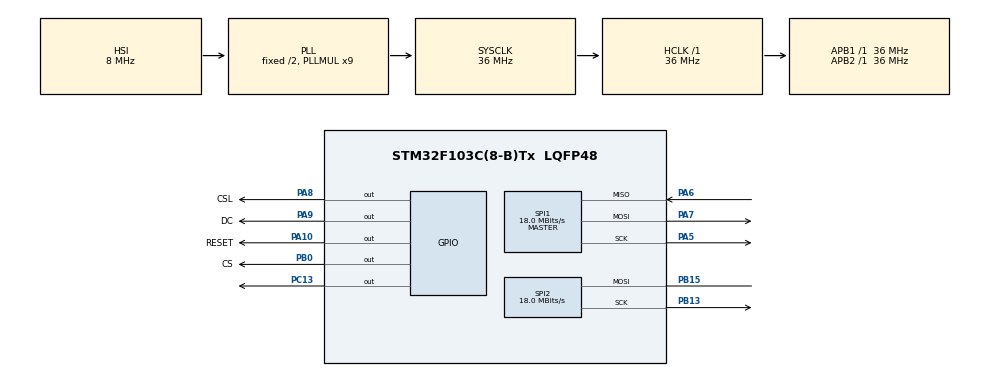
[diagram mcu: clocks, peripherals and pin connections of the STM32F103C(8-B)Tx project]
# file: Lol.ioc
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Mcu.Family=STM32F1
Mcu.Name=STM32F103C(8-B)Tx
Mcu.Package=LQFP48
NVIC.PriorityGroup=NVIC_PRIORITYGROUP_4
PA10.GPIO_Label=RESET
PA10.Signal=GPIO_Output
PA13.Mode=Serial_Wire
PA13.Signal=SYS_JTMS-SWDIO
PA14.Mode=Serial_Wire
PA14.Signal=SYS_JTCK-SWCLK
PA5.Mode=Full_Duplex_Master
PA5.Signal=SPI1_SCK
PA6.Mode=Full_Duplex_Master
PA6.Signal=SPI1_MISO
PA7.Mode=Full_Duplex_Master
PA7.Signal=SPI1_MOSI
PA8.GPIO_Label=CSL
PA8.PinState=GPIO_PIN_SET
PA8.Signal=GPIO_Output
PA9.GPIO_Label=DC
PA9.Signal=GPIO_Output
PB0.GPIO_Label=CS
PB0.Signal=GPIO_Output
PB13.Mode=Simplex_Bidirectional_Master
PB13.Signal=SPI2_SCK
PB15.Mode=Simplex_Bidirectional_Master
PB15.Signal=SPI2_MOSI
PC13-TAMPER-RTC.GPIO_PuPd=GPIO_PULLUP
PC13-TAMPER-RTC.GPIO_Speed=GPIO_SPEED_FREQ_MEDIUM
PC13-TAMPER-RTC.PinState=GPIO_PIN_SET
PC13-TAMPER-RTC.Signal=GPIO_Output
ProjectManager.HeapSize=0x200
ProjectManager.StackSize=0x400
ProjectManager.TargetToolchain=STM32CubeIDE
RCC.AHBFreq_Value=36000000
RCC.APB1Freq_Value=36000000
RCC.APB1TimFreq_Value=36000000
RCC.APB2Freq_Value=36000000
RCC.APB2TimFreq_Value=36000000
RCC.HCLKFreq_Value=36000000
RCC.PLLMUL=RCC_PLL_MUL9
RCC.SYSCLKFreq_VALUE=36000000
RCC.SYSCLKSource=RCC_SYSCLKSOURCE_PLLCLK
RCC.USBFreq_Value=36000000
SPI1.BaudRatePrescaler=SPI_BAUDRATEPRESCALER_2
SPI1.CalculateBaudRate=18.0 MBits/s
SPI1.Direction=SPI_DIRECTION_2LINES
SPI1.Mode=SPI_MODE_MASTER
SPI1.VirtualType=VM_MASTER
SPI2.BaudRatePrescaler=SPI_BAUDRATEPRESCALER_2
SPI2.CalculateBaudRate=18.0 MBits/s
SPI2.Direction=SPI_DIRECTION_1LINE
SPI2.Mode=SPI_MODE_MASTER
SPI2.VirtualType=VM_MASTER
board=custom

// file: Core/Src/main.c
/* USER CODE BEGIN Header */
/**
  ******************************************************************************
  * @file           : main.c
  * @brief          : Main program body
  ******************************************************************************
  * @attention
  *
  * Copyright (c) 2024 STMicroelectronics.
  * All rights reserved.
  *
  * This software is licensed under terms that can be found in the LICENSE file
  * in the root directory of this software component.
  * If no LICENSE file comes with this software, it is provided AS-IS.
  *
  ******************************************************************************
  */
/* USER CODE END Header */
#include "main.h"

/* USER CODE BEGIN Includes */
#include "App/app_main.h"
/* USER CODE END Includes */

SPI_HandleTypeDef hspi1;
SPI_HandleTypeDef hspi2;

void SystemClock_Config(void);
static void MX_GPIO_Init(void);
static void MX_SPI1_Init(void);
static void MX_SPI2_Init(void);

int main(void)
{

  /* MCU Configuration--------------------------------------------------------*/

  /* Reset of all peripherals, Initializes the Flash interface and the Systick. */
  HAL_Init();

  /* Configure the system clock */
  SystemClock_Config();

  /* Initialize all configured peripherals */
  MX_GPIO_Init();
  MX_SPI1_Init();
  MX_SPI2_Init();
  /* USER CODE BEGIN 2 */
  App_main();
  /* USER CODE END 2 */

  /* Infinite loop */
  while (1)
  {

  }
}

void SystemClock_Config(void)
{
  RCC_OscInitTypeDef RCC_OscInitStruct = {0};
  RCC_ClkInitTypeDef RCC_ClkInitStruct = {0};

  /** Initializes the RCC Oscillators according to the specified parameters
  * in the RCC_OscInitTypeDef structure.
  */
  RCC_OscInitStruct.OscillatorType = RCC_OSCILLATORTYPE_HSI;
  RCC_OscInitStruct.HSIState = RCC_HSI_ON;
  RCC_OscInitStruct.HSICalibrationValue = RCC_HSICALIBRATION_DEFAULT;
  RCC_OscInitStruct.PLL.PLLState = RCC_PLL_ON;
  RCC_OscInitStruct.PLL.PLLSource = RCC_PLLSOURCE_HSI_DIV2;
  RCC_OscInitStruct.PLL.PLLMUL = RCC_PLL_MUL9;
  if (HAL_RCC_OscConfig(&RCC_OscInitStruct) != HAL_OK)
  {
    Error_Handler();
  }

  /** Initializes the CPU, AHB and APB buses clocks
  */
  RCC_ClkInitStruct.ClockType = RCC_CLOCKTYPE_HCLK|RCC_CLOCKTYPE_SYSCLK
                              |RCC_CLOCKTYPE_PCLK1|RCC_CLOCKTYPE_PCLK2;
  RCC_ClkInitStruct.SYSCLKSource = RCC_SYSCLKSOURCE_PLLCLK;
  RCC_ClkInitStruct.AHBCLKDivider = RCC_SYSCLK_DIV1;
  RCC_ClkInitStruct.APB1CLKDivider = RCC_HCLK_DIV1;
  RCC_ClkInitStruct.APB2CLKDivider = RCC_HCLK_DIV1;

  if (HAL_RCC_ClockConfig(&RCC_ClkInitStruct, FLASH_LATENCY_1) != HAL_OK)
  {
    Error_Handler();
  }
}

static void MX_SPI1_Init(void)
{

  /* SPI1 parameter configuration*/
  hspi1.Instance = SPI1;
  hspi1.Init.Mode = SPI_MODE_MASTER;
  hspi1.Init.Direction = SPI_DIRECTION_2LINES;
  hspi1.Init.DataSize = SPI_DATASIZE_8BIT;
  hspi1.Init.CLKPolarity = SPI_POLARITY_LOW;
  hspi1.Init.CLKPhase = SPI_PHASE_1EDGE;
  hspi1.Init.NSS = SPI_NSS_SOFT;
  hspi1.Init.BaudRatePrescaler = SPI_BAUDRATEPRESCALER_2;
  hspi1.Init.FirstBit = SPI_FIRSTBIT_MSB;
  hspi1.Init.TIMode = SPI_TIMODE_DISABLE;
  hspi1.Init.CRCCalculation = SPI_CRCCALCULATION_DISABLE;
  hspi1.Init.CRCPolynomial = 10;
  if (HAL_SPI_Init(&hspi1) != HAL_OK)
  {
    Error_Handler();
  }

}

static void MX_SPI2_Init(void)
{

  /* SPI2 parameter configuration*/
  hspi2.Instance = SPI2;
  hspi2.Init.Mode = SPI_MODE_MASTER;
  hspi2.Init.Direction = SPI_DIRECTION_1LINE;
  hspi2.Init.DataSize = SPI_DATASIZE_8BIT;
  hspi2.Init.CLKPolarity = SPI_POLARITY_LOW;
  hspi2.Init.CLKPhase = SPI_PHASE_1EDGE;
  hspi2.Init.NSS = SPI_NSS_SOFT;
  hspi2.Init.BaudRatePrescaler = SPI_BAUDRATEPRESCALER_2;
  hspi2.Init.FirstBit = SPI_FIRSTBIT_MSB;
  hspi2.Init.TIMode = SPI_TIMODE_DISABLE;
  hspi2.Init.CRCCalculation = SPI_CRCCALCULATION_DISABLE;
  hspi2.Init.CRCPolynomial = 10;
  if (HAL_SPI_Init(&hspi2) != HAL_OK)
  {
    Error_Handler();
  }

}

static void MX_GPIO_Init(void)
{
  GPIO_InitTypeDef GPIO_InitStruct = {0};

  /* GPIO Ports Clock Enable */
  __HAL_RCC_GPIOC_CLK_ENABLE();
  __HAL_RCC_GPIOA_CLK_ENABLE();
  __HAL_RCC_GPIOB_CLK_ENABLE();

  /*Configure GPIO pin Output Level */
  HAL_GPIO_WritePin(GPIOC, GPIO_PIN_13, GPIO_PIN_SET);

  /*Configure GPIO pin Output Level */
  HAL_GPIO_WritePin(CS_GPIO_Port, CS_Pin, GPIO_PIN_RESET);

  /*Configure GPIO pin Output Level */
  HAL_GPIO_WritePin(CSL_GPIO_Port, CSL_Pin, GPIO_PIN_SET);

  /*Configure GPIO pin Output Level */
  HAL_GPIO_WritePin(GPIOA, DC_Pin|RESET_Pin, GPIO_PIN_RESET);

  /*Configure GPIO pin : PC13 */
  GPIO_InitStruct.Pin = GPIO_PIN_13;
  GPIO_InitStruct.Mode = GPIO_MODE_OUTPUT_PP;
  GPIO_InitStruct.Pull = GPIO_PULLUP;
  GPIO_InitStruct.Speed = GPIO_SPEED_FREQ_MEDIUM;
  HAL_GPIO_Init(GPIOC, &GPIO_InitStruct);

  /*Configure GPIO pin : CS_Pin */
  GPIO_InitStruct.Pin = CS_Pin;
  GPIO_InitStruct.Mode = GPIO_MODE_OUTPUT_PP;
  GPIO_InitStruct.Pull = GPIO_NOPULL;
  GPIO_InitStruct.Speed = GPIO_SPEED_FREQ_LOW;
  HAL_GPIO_Init(CS_GPIO_Port, &GPIO_InitStruct);

  /*Configure GPIO pins : CSL_Pin DC_Pin RESET_Pin */
  GPIO_InitStruct.Pin = CSL_Pin|DC_Pin|RESET_Pin;
  GPIO_InitStruct.Mode = GPIO_MODE_OUTPUT_PP;
  GPIO_InitStruct.Pull = GPIO_NOPULL;
  GPIO_InitStruct.Speed = GPIO_SPEED_FREQ_LOW;
  HAL_GPIO_Init(GPIOA, &GPIO_InitStruct);

}

void Error_Handler(void)
{
  __disable_irq();
  while (1)
  {
  }
}
